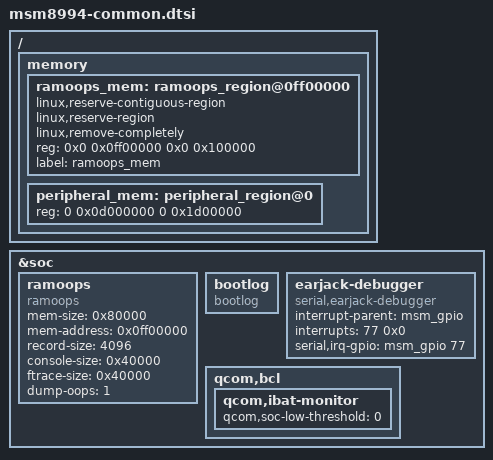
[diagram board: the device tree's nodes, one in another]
/* Copyright (c) 2014, The Linux Foundation. All rights reserved.
 *
 * This program is free software; you can redistribute it and/or modify
 * it under the terms of the GNU General Public License version 2 and
 * only version 2 as published by the Free Software Foundation.
 *
 * This program is distributed in the hope that it will be useful,
 * but WITHOUT ANY WARRANTY; without even the implied warranty of
 * MERCHANTABILITY or FITNESS FOR A PARTICULAR PURPOSE.  See the
 * GNU General Public License for more details.
 */

/ {
	memory {
		ramoops_mem: ramoops_region@0ff00000 {
			linux,reserve-contiguous-region;
			linux,reserve-region;
			linux,remove-completely;
			reg = <0x0 0x0ff00000 0x0 0x100000>;
			label = "ramoops_mem";
		};
		peripheral_mem: peripheral_region@0 {
			reg = <0 0x0d000000 0 0x1d00000>;
		};
	};
};

&soc {
	ramoops {
		compatible = "ramoops";
		mem-size = <0x80000>;
		mem-address = <0x0ff00000>;
		record-size = <4096>;
		console-size = <0x40000>;
		ftrace-size = <0x40000>;
		dump-oops = <1>;
	};

	bootlog {
		compatible = "bootlog";
	};

	earjack-debugger {
		compatible = "serial,earjack-debugger";
		status = "ok";
		interrupt-parent = <&msm_gpio>;
		interrupts = <77 0x0>;
		serial,irq-gpio = <&msm_gpio 77 0x00>;
	};

	qcom,bcl {
		qcom,ibat-monitor {
			qcom,soc-low-threshold = <0>;
		};
	};
};
